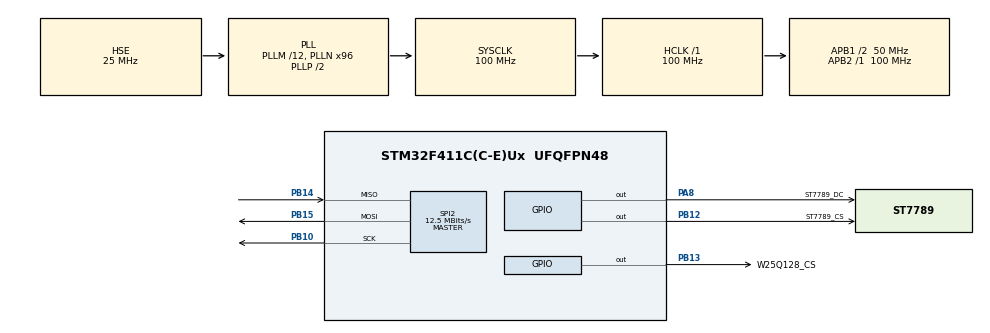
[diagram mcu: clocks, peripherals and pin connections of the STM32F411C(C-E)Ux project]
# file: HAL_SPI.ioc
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Dma.Request0=SPI2_RX
Dma.Request1=SPI2_TX
Dma.SPI2_RX.0.Direction=DMA_PERIPH_TO_MEMORY
Dma.SPI2_RX.0.FIFOMode=DMA_FIFOMODE_DISABLE
Dma.SPI2_RX.0.Instance=DMA1_Stream3
Dma.SPI2_RX.0.MemDataAlignment=DMA_MDATAALIGN_BYTE
Dma.SPI2_RX.0.MemInc=DMA_MINC_ENABLE
Dma.SPI2_RX.0.Mode=DMA_NORMAL
Dma.SPI2_RX.0.PeriphDataAlignment=DMA_PDATAALIGN_BYTE
Dma.SPI2_RX.0.PeriphInc=DMA_PINC_DISABLE
Dma.SPI2_RX.0.Priority=DMA_PRIORITY_LOW
Dma.SPI2_TX.1.Direction=DMA_MEMORY_TO_PERIPH
Dma.SPI2_TX.1.FIFOMode=DMA_FIFOMODE_DISABLE
Dma.SPI2_TX.1.Instance=DMA1_Stream4
Dma.SPI2_TX.1.MemDataAlignment=DMA_MDATAALIGN_BYTE
Dma.SPI2_TX.1.MemInc=DMA_MINC_ENABLE
Dma.SPI2_TX.1.Mode=DMA_NORMAL
Dma.SPI2_TX.1.PeriphDataAlignment=DMA_PDATAALIGN_BYTE
Dma.SPI2_TX.1.PeriphInc=DMA_PINC_DISABLE
Dma.SPI2_TX.1.Priority=DMA_PRIORITY_LOW
Mcu.Family=STM32F4
Mcu.Name=STM32F411C(C-E)Ux
Mcu.Package=UFQFPN48
NVIC.DMA1_Stream3_IRQn=true\:0\:0\:false\:false\:true\:false\:true\:true
NVIC.DMA1_Stream4_IRQn=true\:0\:0\:false\:false\:true\:false\:true\:true
NVIC.PriorityGroup=NVIC_PRIORITYGROUP_4
NVIC.SPI2_IRQn=true\:5\:0\:true\:false\:true\:true\:true\:true
PA13.Mode=Serial_Wire
PA13.Signal=SYS_JTMS-SWDIO
PA14.Mode=Serial_Wire
PA14.Signal=SYS_JTCK-SWCLK
PA8.GPIO_Label=ST7789_DC
PA8.GPIO_PuPd=GPIO_PULLUP
PA8.GPIO_Speed=GPIO_SPEED_FREQ_VERY_HIGH
PA8.PinState=GPIO_PIN_RESET
PA8.Signal=GPIO_Output
PB10.Mode=Full_Duplex_Master
PB10.Signal=SPI2_SCK
PB12.GPIO_Label=ST7789_CS
PB12.GPIO_PuPd=GPIO_PULLUP
PB12.GPIO_Speed=GPIO_SPEED_FREQ_VERY_HIGH
PB12.PinState=GPIO_PIN_SET
PB12.Signal=GPIO_Output
PB13.GPIO_Label=W25Q128_CS
PB13.GPIO_PuPd=GPIO_PULLUP
PB13.GPIO_Speed=GPIO_SPEED_FREQ_VERY_HIGH
PB13.PinState=GPIO_PIN_SET
PB13.Signal=GPIO_Output
PB14.Mode=Full_Duplex_Master
PB14.Signal=SPI2_MISO
PB15.Mode=Full_Duplex_Master
PB15.Signal=SPI2_MOSI
PB3.Signal=SYS_JTDO-SWO
PH0\ -\ OSC_IN.Mode=HSE-External-Oscillator
PH0\ -\ OSC_IN.Signal=RCC_OSC_IN
PH1\ -\ OSC_OUT.Mode=HSE-External-Oscillator
PH1\ -\ OSC_OUT.Signal=RCC_OSC_OUT
ProjectManager.HeapSize=0x200
ProjectManager.StackSize=0x400
ProjectManager.TargetToolchain=CMake
RCC.48MHZClocksFreq_Value=50000000
RCC.AHBFreq_Value=100000000
RCC.APB1CLKDivider=RCC_HCLK_DIV2
RCC.APB1Freq_Value=50000000
RCC.APB1TimFreq_Value=100000000
RCC.APB2Freq_Value=100000000
RCC.APB2TimFreq_Value=100000000
RCC.CortexFreq_Value=100000000
RCC.HCLKFreq_Value=100000000
RCC.HSE_VALUE=25000000
RCC.HSI_VALUE=16000000
RCC.LSE_VALUE=32768
RCC.PLLM=12
RCC.PLLN=96
RCC.PLLSourceVirtual=RCC_PLLSOURCE_HSE
RCC.SYSCLKFreq_VALUE=100000000
RCC.SYSCLKSource=RCC_SYSCLKSOURCE_PLLCLK
RCC.VCOOutputFreq_Value=200000000
SPI2.BaudRatePrescaler=SPI_BAUDRATEPRESCALER_4
SPI2.CalculateBaudRate=12.5 MBits/s
SPI2.Direction=SPI_DIRECTION_2LINES
SPI2.Mode=SPI_MODE_MASTER
SPI2.VirtualType=VM_MASTER
board=custom

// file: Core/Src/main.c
/* USER CODE BEGIN Header */
/**
  ******************************************************************************
  * @file           : main.c
  * @brief          : Main program body
  ******************************************************************************
  * @attention
  *
  * Copyright (c) 2026 STMicroelectronics.
  * All rights reserved.
  *
  * This software is licensed under terms that can be found in the LICENSE file
  * in the root directory of this software component.
  * If no LICENSE file comes with this software, it is provided AS-IS.
  *
  ******************************************************************************
  */
/* USER CODE END Header */
#include "main.h"

/* USER CODE BEGIN Includes */
#include <stdio.h>
#include "ST7789.h"
#include "SPI_Driver.h"
#include "W25Q128.h"
/* USER CODE END Includes */

SPI_HandleTypeDef hspi2;
DMA_HandleTypeDef hdma_spi2_rx;
DMA_HandleTypeDef hdma_spi2_tx;

void SystemClock_Config(void);
static void MX_GPIO_Init(void);
static void MX_DMA_Init(void);
static void MX_SPI2_Init(void);
/* USER CODE BEGIN PFP */

SPI_Bus_t SPI_Bus = {
  .hspi =               &hspi2,
  .current_dev_config = W25Q128_Dev,
  .bus_state =          SPI_Bus_Idle
};

/* USER CODE END PFP */

int main(void)
{

  /* MCU Configuration--------------------------------------------------------*/

  /* Reset of all peripherals, Initializes the Flash interface and the Systick. */
  HAL_Init();

  /* Configure the system clock */
  SystemClock_Config();

  /* Initialize all configured peripherals */
  MX_GPIO_Init();
  MX_DMA_Init();
  MX_SPI2_Init();

  /* Infinite loop */
  while (1)
  {

  }
}

void SystemClock_Config(void)
{
  RCC_OscInitTypeDef RCC_OscInitStruct = {0};
  RCC_ClkInitTypeDef RCC_ClkInitStruct = {0};

  /** Configure the main internal regulator output voltage
  */
  __HAL_RCC_PWR_CLK_ENABLE();
  __HAL_PWR_VOLTAGESCALING_CONFIG(PWR_REGULATOR_VOLTAGE_SCALE1);

  /** Initializes the RCC Oscillators according to the specified parameters
  * in the RCC_OscInitTypeDef structure.
  */
  RCC_OscInitStruct.OscillatorType = RCC_OSCILLATORTYPE_HSE;
  RCC_OscInitStruct.HSEState = RCC_HSE_ON;
  RCC_OscInitStruct.PLL.PLLState = RCC_PLL_ON;
  RCC_OscInitStruct.PLL.PLLSource = RCC_PLLSOURCE_HSE;
  RCC_OscInitStruct.PLL.PLLM = 12;
  RCC_OscInitStruct.PLL.PLLN = 96;
  RCC_OscInitStruct.PLL.PLLP = RCC_PLLP_DIV2;
  RCC_OscInitStruct.PLL.PLLQ = 4;
  if (HAL_RCC_OscConfig(&RCC_OscInitStruct) != HAL_OK)
  {
    Error_Handler();
  }

  /** Initializes the CPU, AHB and APB buses clocks
  */
  RCC_ClkInitStruct.ClockType = RCC_CLOCKTYPE_HCLK|RCC_CLOCKTYPE_SYSCLK
                              |RCC_CLOCKTYPE_PCLK1|RCC_CLOCKTYPE_PCLK2;
  RCC_ClkInitStruct.SYSCLKSource = RCC_SYSCLKSOURCE_PLLCLK;
  RCC_ClkInitStruct.AHBCLKDivider = RCC_SYSCLK_DIV1;
  RCC_ClkInitStruct.APB1CLKDivider = RCC_HCLK_DIV2;
  RCC_ClkInitStruct.APB2CLKDivider = RCC_HCLK_DIV1;

  if (HAL_RCC_ClockConfig(&RCC_ClkInitStruct, FLASH_LATENCY_3) != HAL_OK)
  {
    Error_Handler();
  }
}

static void MX_SPI2_Init(void)
{

  /* SPI2 parameter configuration*/
  hspi2.Instance = SPI2;
  hspi2.Init.Mode = SPI_MODE_MASTER;
  hspi2.Init.Direction = SPI_DIRECTION_2LINES;
  hspi2.Init.DataSize = SPI_DATASIZE_8BIT;
  hspi2.Init.CLKPolarity = SPI_POLARITY_LOW;
  hspi2.Init.CLKPhase = SPI_PHASE_1EDGE;
  hspi2.Init.NSS = SPI_NSS_SOFT;
  hspi2.Init.BaudRatePrescaler = SPI_BAUDRATEPRESCALER_4;
  hspi2.Init.FirstBit = SPI_FIRSTBIT_MSB;
  hspi2.Init.TIMode = SPI_TIMODE_DISABLE;
  hspi2.Init.CRCCalculation = SPI_CRCCALCULATION_DISABLE;
  hspi2.Init.CRCPolynomial = 10;
  if (HAL_SPI_Init(&hspi2) != HAL_OK)
  {
    Error_Handler();
  }

}

static void MX_DMA_Init(void)
{

  /* DMA controller clock enable */
  __HAL_RCC_DMA1_CLK_ENABLE();

  /* DMA interrupt init */
  /* DMA1_Stream3_IRQn interrupt configuration */
  HAL_NVIC_SetPriority(DMA1_Stream3_IRQn, 0, 0);
  HAL_NVIC_EnableIRQ(DMA1_Stream3_IRQn);
  /* DMA1_Stream4_IRQn interrupt configuration */
  HAL_NVIC_SetPriority(DMA1_Stream4_IRQn, 0, 0);
  HAL_NVIC_EnableIRQ(DMA1_Stream4_IRQn);

}

static void MX_GPIO_Init(void)
{
  GPIO_InitTypeDef GPIO_InitStruct = {0};

  /* GPIO Ports Clock Enable */
  __HAL_RCC_GPIOH_CLK_ENABLE();
  __HAL_RCC_GPIOB_CLK_ENABLE();
  __HAL_RCC_GPIOA_CLK_ENABLE();

  /*Configure GPIO pin Output Level */
  HAL_GPIO_WritePin(GPIOB, ST7789_CS_Pin|W25Q128_CS_Pin, GPIO_PIN_SET);

  /*Configure GPIO pin Output Level */
  HAL_GPIO_WritePin(ST7789_DC_GPIO_Port, ST7789_DC_Pin, GPIO_PIN_RESET);

  /*Configure GPIO pins : ST7789_CS_Pin W25Q128_CS_Pin */
  GPIO_InitStruct.Pin = ST7789_CS_Pin|W25Q128_CS_Pin;
  GPIO_InitStruct.Mode = GPIO_MODE_OUTPUT_PP;
  GPIO_InitStruct.Pull = GPIO_PULLUP;
  GPIO_InitStruct.Speed = GPIO_SPEED_FREQ_VERY_HIGH;
  HAL_GPIO_Init(GPIOB, &GPIO_InitStruct);

  /*Configure GPIO pin : ST7789_DC_Pin */
  GPIO_InitStruct.Pin = ST7789_DC_Pin;
  GPIO_InitStruct.Mode = GPIO_MODE_OUTPUT_PP;
  GPIO_InitStruct.Pull = GPIO_PULLUP;
  GPIO_InitStruct.Speed = GPIO_SPEED_FREQ_VERY_HIGH;
  HAL_GPIO_Init(ST7789_DC_GPIO_Port, &GPIO_InitStruct);

}

void Error_Handler(void)
{
  __disable_irq();
  while (1)
  {
  }
}
